# System_Clock_FLLPLUS_5 register map
Vendor: Texas Instruments
Peripheral module from a debugger description file (folder msp430).
Registers are 8-bit, read-write, reset 0x0 unless marked. A register's access mark holds for its fields unless they carry their own. Offsets are as the file gives them; lines under a group give offsets from that group; [hi:lo] are bit positions; {n}, {i} and the like mark numbered series; 'fields as' and 'values as' point back to an identical list; <NAME> marks a mode.

## System_Clock_FLLPLUS
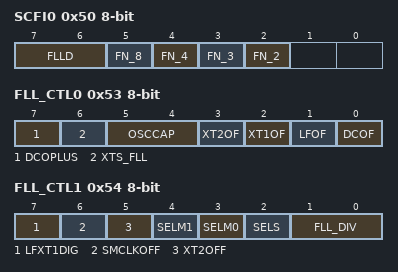
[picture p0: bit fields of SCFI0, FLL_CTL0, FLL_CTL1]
0x50 SCFI0 — System Clock Frequency Integrator 0
  [7:6] FLLD — Loop Divider Bit : 0
  [5] FN_8 — fDCOCLK = 5-40Mhz
  [4] FN_4 — fDCOCLK = 3.2-25Mhz
  [3] FN_3 — fDCOCLK = 2.2-17Mhz
  [2] FN_2 — fDCOCLK = 1.4-12MHz
0x51 SCFI1 access not given reset not defined — System Clock Frequency Integrator 1
0x52 SCFQCTL access not given reset not defined — System Clock Frequency Control
0x53 FLL_CTL0 — FLL+ Control 0
  [7] DCOPLUS — DCO+ Enable
  [6] XTS_FLL — 1: Selects high-freq. oscillator
  [5:4] OSCCAP — XIN/XOUT Cap 0
    {v}=XIN Cap = XOUT Cap: {v} (v=0..3)
  [3] XT2OF — High Frequency Oscillator 2 Fault Flag
  [2] XT1OF — High Frequency Oscillator 1 Fault Flag
  [1] LFOF — Low Frequency Oscillator Fault Flag
  [0] DCOF — DCO Fault Flag
0x54 FLL_CTL1 — FLL+ Control 1
  [7] LFXT1DIG — Enable Digital input for LF clock
  [6] SMCLKOFF — Peripheral Module Clock (SMCLK) disable
  [5] XT2OFF — High Frequency Oscillator 2 (XT2) disable
  [4] SELM1 — MCLK Source Select 1
  [3] SELM0 — MCLK Source Select 0
  [2] SELS — Peripheral Module Clock Source (0: DCO
  [1:0] FLL_DIV — FLL+ Divide Px.x/ACLK 0
0x55 FLL_CTL2 — FLL+ Control 2
  [7:6] XT2S — Mode 0 for XT2
    0=Mode 0 for XT2 : 0.4 - 1 MHz; 1=Mode 1 for XT2 : 1 - 4 MHz; 2=Mode 2 for XT2 : 2 - 16 MHz; 3=Mode 3 for XT2 : Digital input signal
